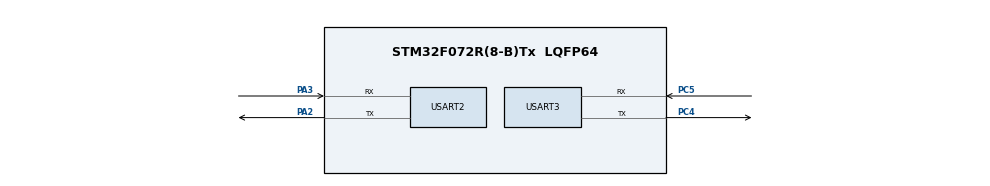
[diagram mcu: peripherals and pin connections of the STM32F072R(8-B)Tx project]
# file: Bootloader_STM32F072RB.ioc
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Mcu.Family=STM32F0
Mcu.Name=STM32F072R(8-B)Tx
Mcu.Package=LQFP64
PA2.Mode=Asynchronous
PA2.Signal=USART2_TX
PA3.Mode=Asynchronous
PA3.Signal=USART2_RX
PC4.Mode=Asynchronous
PC4.Signal=USART3_TX
PC5.Mode=Asynchronous
PC5.Signal=USART3_RX
ProjectManager.HeapSize=0x200
ProjectManager.StackSize=0x400
ProjectManager.TargetToolchain=STM32CubeIDE
USART2.VirtualMode-Asynchronous=VM_ASYNC
USART3.VirtualMode-Asynchronous=VM_ASYNC
VP_CRC_VS_CRC.Mode=CRC_Activate
board=custom

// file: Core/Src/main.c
/* USER CODE BEGIN Header */
/**
  ******************************************************************************
  * @file           : main.c
  * @brief          : Main program body
  ******************************************************************************
  * @attention
  *
  * Copyright (c) 2025 STMicroelectronics.
  * All rights reserved.
  *
  * This software is licensed under terms that can be found in the LICENSE file
  * in the root directory of this software component.
  * If no LICENSE file comes with this software, it is provided AS-IS.
  *
  ******************************************************************************
  */
/* USER CODE END Header */
#include "main.h"
#include "stm32f0xx_hal.h"
#include <stdarg.h>
#include <string.h>
#include <stdio.h>

/* USER CODE BEGIN PM */
#define BL_DEBUG_MSG_EN

/* USER CODE END PM */

CRC_HandleTypeDef hcrc;

UART_HandleTypeDef huart2;
UART_HandleTypeDef huart3;

#define D_UART &huart3
#define C_UART &huart2

void SystemClock_Config(void);
static void MX_GPIO_Init(void);
static void MX_CRC_Init(void);
static void MX_USART2_UART_Init(void);
static void MX_USART3_UART_Init(void);
static void printmsg(char *format,...);

int main(void)
{

  /* MCU Configuration--------------------------------------------------------*/

  /* Reset of all peripherals, Initializes the Flash interface and the Systick. */
  HAL_Init();

  /* Configure the system clock */
  SystemClock_Config();

  /* Initialize all configured peripherals */
  MX_GPIO_Init();
  MX_CRC_Init();
  MX_USART2_UART_Init();
  MX_USART3_UART_Init();

  if (HAL_GPIO_ReadPin(GPIOC, GPIO_PIN_13) == GPIO_PIN_RESET)
  {
	  printmsg("BL_DEBUG_MSG: Button is pressed .. going to BL mode \n\r");

	  bootloader_uart_read_data();
  }
  else
  {
	  printmsg("BL_DEBUG_MSG: Button is not pressed .. executing user app \n");
	  bootloader_jump_to_user_app();
  }

}

void bootloader_uart_read_data(void)
{

}

void bootloader_jump_to_user_app(void)
{

}

/* prints formatted string to console over UART */
void printmsg(char *format,...)
{
#ifdef BL_DEBUG_MSG_EN
	char str[80];

	/* Extract the arument list using VA apis*/
	va_list args;
	va_start(args, format);
	vsprintf(str, format, args);
	HAL_UART_Transmit(D_UART, (uint8_t *)str, strlen(str), HAL_MAX_DELAY);
	va_end(args);
#endif

}

void SystemClock_Config(void)
{
  RCC_OscInitTypeDef RCC_OscInitStruct = {0};
  RCC_ClkInitTypeDef RCC_ClkInitStruct = {0};
  RCC_PeriphCLKInitTypeDef PeriphClkInit = {0};

  /** Initializes the RCC Oscillators according to the specified parameters
  * in the RCC_OscInitTypeDef structure.
  */
  RCC_OscInitStruct.OscillatorType = RCC_OSCILLATORTYPE_HSI;
  RCC_OscInitStruct.HSIState = RCC_HSI_ON;
  RCC_OscInitStruct.HSICalibrationValue = RCC_HSICALIBRATION_DEFAULT;
  RCC_OscInitStruct.PLL.PLLState = RCC_PLL_NONE;
  if (HAL_RCC_OscConfig(&RCC_OscInitStruct) != HAL_OK)
  {
    Error_Handler();
  }

  /** Initializes the CPU, AHB and APB buses clocks
  */
  RCC_ClkInitStruct.ClockType = RCC_CLOCKTYPE_HCLK|RCC_CLOCKTYPE_SYSCLK
                              |RCC_CLOCKTYPE_PCLK1;
  RCC_ClkInitStruct.SYSCLKSource = RCC_SYSCLKSOURCE_HSI;
  RCC_ClkInitStruct.AHBCLKDivider = RCC_SYSCLK_DIV1;
  RCC_ClkInitStruct.APB1CLKDivider = RCC_HCLK_DIV1;

  if (HAL_RCC_ClockConfig(&RCC_ClkInitStruct, FLASH_LATENCY_0) != HAL_OK)
  {
    Error_Handler();
  }
  PeriphClkInit.PeriphClockSelection = RCC_PERIPHCLK_USART2;
  PeriphClkInit.Usart2ClockSelection = RCC_USART2CLKSOURCE_PCLK1;
  if (HAL_RCCEx_PeriphCLKConfig(&PeriphClkInit) != HAL_OK)
  {
    Error_Handler();
  }
}

static void MX_CRC_Init(void)
{

  hcrc.Instance = CRC;
  hcrc.Init.DefaultPolynomialUse = DEFAULT_POLYNOMIAL_ENABLE;
  hcrc.Init.DefaultInitValueUse = DEFAULT_INIT_VALUE_ENABLE;
  hcrc.Init.InputDataInversionMode = CRC_INPUTDATA_INVERSION_NONE;
  hcrc.Init.OutputDataInversionMode = CRC_OUTPUTDATA_INVERSION_DISABLE;
  hcrc.InputDataFormat = CRC_INPUTDATA_FORMAT_BYTES;
  if (HAL_CRC_Init(&hcrc) != HAL_OK)
  {
    Error_Handler();
  }

}

static void MX_USART2_UART_Init(void)
{

  huart2.Instance = USART2;
  huart2.Init.BaudRate = 38400;
  huart2.Init.WordLength = UART_WORDLENGTH_8B;
  huart2.Init.StopBits = UART_STOPBITS_1;
  huart2.Init.Parity = UART_PARITY_NONE;
  huart2.Init.Mode = UART_MODE_TX_RX;
  huart2.Init.HwFlowCtl = UART_HWCONTROL_NONE;
  huart2.Init.OverSampling = UART_OVERSAMPLING_16;
  huart2.Init.OneBitSampling = UART_ONE_BIT_SAMPLE_DISABLE;
  huart2.AdvancedInit.AdvFeatureInit = UART_ADVFEATURE_NO_INIT;
  if (HAL_UART_Init(&huart2) != HAL_OK)
  {
    Error_Handler();
  }

}

static void MX_USART3_UART_Init(void)
{

  huart3.Instance = USART3;
  huart3.Init.BaudRate = 38400;
  huart3.Init.WordLength = UART_WORDLENGTH_8B;
  huart3.Init.StopBits = UART_STOPBITS_1;
  huart3.Init.Parity = UART_PARITY_NONE;
  huart3.Init.Mode = UART_MODE_TX_RX;
  huart3.Init.HwFlowCtl = UART_HWCONTROL_NONE;
  huart3.Init.OverSampling = UART_OVERSAMPLING_16;
  huart3.Init.OneBitSampling = UART_ONE_BIT_SAMPLE_DISABLE;
  huart3.AdvancedInit.AdvFeatureInit = UART_ADVFEATURE_NO_INIT;
  if (HAL_UART_Init(&huart3) != HAL_OK)
  {
    Error_Handler();
  }

}

static void MX_GPIO_Init(void)
{

  /* GPIO Ports Clock Enable */
  __HAL_RCC_GPIOA_CLK_ENABLE();
  __HAL_RCC_GPIOC_CLK_ENABLE();

}

void Error_Handler(void)
{
  __disable_irq();
  while (1)
  {
  }
}
